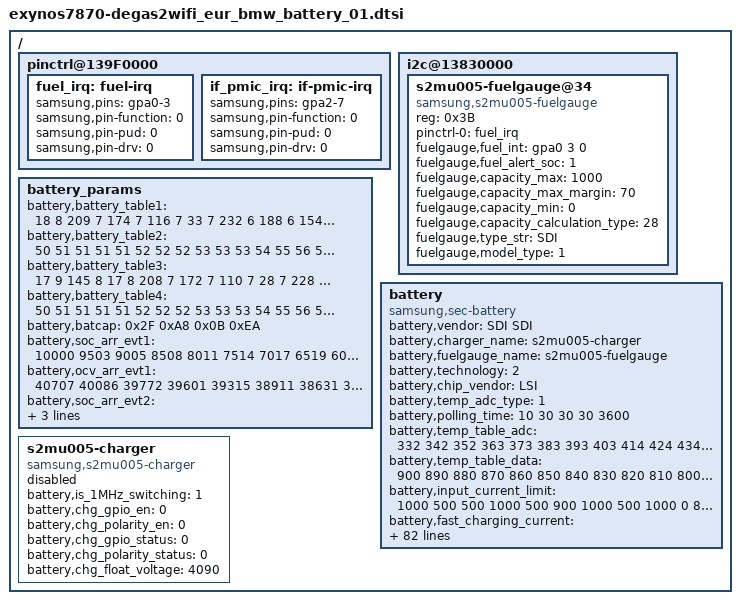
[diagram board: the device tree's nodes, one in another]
/*
 * SAMSUNG UNIVERSAL5433 board device tree source
 *
 * Copyright (c) 2015 Samsung Electronics Co., Ltd.
 *		http://www.samsung.com
 *
 * This program is free software; you can redistribute it and/or modify
 * it under the terms of the GNU General Public License version 2 as
 * published by the Free Software Foundation.
*/

/ {
	pinctrl@139F0000 {
		fuel_irq: fuel-irq {
			samsung,pins = "gpa0-3";
			samsung,pin-function = <0>;
			samsung,pin-pud = <0>;
			samsung,pin-drv = <0>;
		};
	};

	pinctrl@139F0000 {
		if_pmic_irq: if-pmic-irq {
			samsung,pins = "gpa2-7";
			samsung,pin-function = <0>;
			samsung,pin-pud = <0>;
			samsung,pin-drv = <0>;
		};
	};

	i2c@13830000 {
		status = "okay";
		s2mu005-fuelgauge@34 {
			compatible = "samsung,s2mu005-fuelgauge";
			reg = <0x3B>;
			pinctrl-names = "default";
			pinctrl-0 = <&fuel_irq>;
			fuelgauge,fuel_int = <&gpa0 3 0>;
			fuelgauge,fuel_alert_soc = <1>;
			fuelgauge,capacity_max = <1000>;
			fuelgauge,capacity_max_margin = <70>;
			fuelgauge,capacity_min = <0>;
			fuelgauge,capacity_calculation_type = <28>;
			fuelgauge,type_str = "SDI";
			fuelgauge,model_type = <1>;
		};
	};

	battery_params {
			battery,battery_table1 = <18 8 209 7 174 7 116 7 33 7 232 6 188 6 154 6 125 6 100 6 78 6 59 6 38 6 19 6 250 5 208 5 156 5 138 5 93 5 109 3 108
			                                      3 109 1 0 8 154 7 52 7 206 6 105 6 3 6 157 5 55 5 209 4 107 4 6 4 160 3 58 3 212 2 111 2 9 2 163 1 61 1 215 0 113 0 12 0 235 15>;

			battery,battery_table2 = <50 51 51 51 51 52 52 52 53 53 53 54 55 56 56 57 57 58 58 59 61 154>;
			
			battery,battery_table3 = <17 9 145 8 17 8 208 7 172 7 110 7 28 7 228 6 185 6 150 6 121 6 97 6 75 6 55 6 34 6 13 6 240 5 195 5 151 5 125 5 198 
			                                     4 109 1 103 8 0 8 153 7 49 7 202 6 98 6 251 5 147 5 44 5 196 4 93 4 246 3 142 3 39 3 191 2 88 2 240 1 137 1 33 1 186 0 83 0 235 15>;
			battery,battery_table4 = <50 51 51 51 51 52 52 52 53 53 53 54 55 56 56 57 57 58 58 59 61 154>;

			battery,batcap = <0x2F 0xA8 0x0B 0xEA>; /* [0x0F] [0x0E] [0x11] [0x10] */
			
			battery,soc_arr_evt1 = <10000 9503 9005 8508 8011 7514 7017 6519 6022 5525 5028 4531 4034 3537 3040 2542 2046 1549 1052 554 57 (-100)>;
			battery,ocv_arr_evt1 = <40707 40086 39772 39601 39315 38911 38631 38420 38252 38110 37989 37882 37788 37688 37593 37473 37265 37010 36923 36705 34276 31700>;
			
			battery,soc_arr_evt2 = <10000 9503 9005 8508 8011 7514 7017 6519 6022 5525 5028 4531 4034 3537 3040 2542 2046 1549 1052 554 57 (-100)>;
			battery,ocv_arr_evt2 = <40707 40086 39772 39601 39315 38911 38631 38420 38252 38110 37989 37882 37788 37688 37593 37473 37265 37010 36923 36705 34276 31700>;
	};

	battery {
		status = "okay";

		pinctrl-names = "default";

		compatible = "samsung,sec-battery";
		battery,vendor = "SDI SDI";
		battery,charger_name = "s2mu005-charger";
		battery,fuelgauge_name = "s2mu005-fuelgauge";
		battery,technology = <2>; /* POWER_SUPPLY_TECHNOLOGY_LION */

		battery,chip_vendor = "LSI";
		battery,temp_adc_type = <1>; /* SEC_BATTERY_ADC_TYPE_AP */

		battery,polling_time = <10 30 30 30 3600>;

		battery,temp_table_adc = <332 342 352 363 373 383 393 403 414 424 434 450 466 482 498 515 530
					546 561 577 593 610 627 644 661 681 701 722 744 769 794 817 841 856 872
					924 966 1007 1022 1038 1068 1099 1136 1170 1205 1242 1288 1324 1360 1409 1459
					1495 1532 1568 1605 1642 1692 1743 1793 1844 1895 1933 1972 2010 2049 2088 2126
					2165 2203 2242 2281 2317 2353 2389 2425 2461 2509 2557 2605 2653 2702 2734 2767
					2800 2832 2865 2898 2931 2965 2998 3030 3060 3090 3118 3147 3177 3214 3239 3263
					3288 3313 3331 3349 3367 3386 3404 3409 3418 3426 3434 3442>;

		battery,temp_table_data = <900 890 880 870 860 850 840 830 820 810 800 790 780 770 760 750 740 730 720 710 700 690
					   680 670 660 650 640 630 620 610 600 590 580 570 560 550 540 530 520 510 500 490 480 470
					   460 450 440 430 420 410 400 390 380 370 360 350 340 330 320 310 300 290 280 270 260 250
					   240 230 220 210 200 190 180 170 160 150 140 130 120 110 100 90 80 70 60 50 40 30 20 10
					   0 (-10) (-20) (-30) (-40) (-50) (-60) (-70) (-80) (-90) (-100) (-110) (-120) (-130) (-140)
					   (-150) (-160) (-170) (-180) (-190) (-200)>;

		battery,input_current_limit = <1000 500 500 1000 500 900 1000 500 1000 0 820 820 820 1000 1000 0 0 400 700 1000 300 1000 1000 0 1000 1000 1000 1000 80 1000 1000 1000 1000 1000 820 820>;
		battery,fast_charging_current = <1000 0 0 1000 500 1000 1000 500 1000 0 1000 1000 1000 1000 1000 0 0 400 700 1000 300 1000 1000 0 1000 1000 1000 1000 80 1000 1000 1000 0 1000 1000 1000>;
		battery,full_check_current_1st = <200 0 0 200 200 200 200 200 200 0 200 200 200 200 200 0 0 200 200 200 200 200 200 0 200 200 200 200 0 200 200 200 0 200 200 200>;
		battery,full_check_current_2nd = <150 0 0 150 150 150 150 150 150 0 150 150 150 150 150 0 0 150 150 150 150 150 150 0 150 150 150 150 0 150 150 150 0 150 150 150>;

		battery,wireless_cc_cv = <86>;
		battery,inbat_voltage = <0>;
		battery,inbat_voltage_table_adc = <3120 3101 3061 3038 3001 2956 2920 2887 2856 2814
						2793 2754 2720 2677 2641 2613 2572 2531 2502 2467 2436>;
		battery,inbat_voltage_table_data = <438 435 430 425 420 415 410 405 400 395
						390 385 380 375 370 365 360 355 350 345 340>;

		battery,adc_check_count = <5>;

		battery,cable_check_type = <4>; /* SEC_BATTERY_CABLE_CHECK_PSY */
		battery,cable_source_type = <1>; /* SEC_BATTERY_CABLE_SOURCE_EXTERNAL */
		battery,polling_type = <1>; /* SEC_BATTERY_MONITOR_ALARM */
		battery,monitor_initial_count = <0>;

		battery,battery_check_type = <0>; /* SEC_BATTERY_CHECK_NONE */
		battery,check_count = <0>;

		battery,check_adc_max = <1440>;
		battery,check_adc_min = <0>;

		battery,ovp_uvlo_check_type = <3>; /* SEC_BATTERY_OVP_UVLO_CHGPOLLING */

		battery,thermal_source = <2>; /* SEC_BATTERY_THERMAL_SOURCE_ADC */

		battery,temp_check_type = <2>; /* SEC_BATTERY_TEMP_CHECK_TEMP */
		battery,temp_check_count = <1>;
		battery,temp_highlimit_threshold_normal = <800>;
		battery,temp_highlimit_recovery_normal = <750>;
		battery,temp_high_threshold_normal = <500>;
		battery,temp_high_recovery_normal = <450>;
		battery,temp_low_threshold_normal = <0>;
		battery,temp_low_recovery_normal = <5>;
		battery,temp_highlimit_threshold_lpm = <800>;
		battery,temp_highlimit_recovery_lpm = <750>;
		battery,temp_high_threshold_lpm = <500>;
		battery,temp_high_recovery_lpm = <450>;
		battery,temp_low_threshold_lpm = <0>;
		battery,temp_low_recovery_lpm = <5>;
		battery,full_check_type = <2>; /* SEC_BATTERY_FULLCHARGED_FG_CURRENT */
		battery,full_check_type_2nd = <0>; /* NONE */
		battery,full_check_count = <1>;
		battery,chg_gpio_full_check = <0>;
		battery,chg_polarity_full_check = <1>;

		battery,chg_high_temp_1st = <530>;
		battery,chg_high_temp_2nd = <530>;
		battery,chg_high_temp_recovery = <525>;
		battery,chg_charging_limit_current = <1300>;
		battery,chg_charging_limit_current_2nd = <1300>;
		battery,chg_skip_check_capacity = <10>;
		battery,chg_skip_check_time = <600>;

		battery,wpc_high_temp = <420>;
		battery,wpc_high_temp_recovery = <410>;
		battery,wpc_charging_limit_current = <450>;

		/* SEC_BATTERY_FULL_CONDITION_SOC |
		   SEC_BATTERY_FULL_CONDITION_NOTIMEFULL |
		   SEC_BATTERY_FULL_CONDITION_VCELL */
		battery,full_condition_type = <15>;
		battery,full_condition_soc = <93>;
		battery,full_condition_vcell = <4000>;

		battery,recharge_check_count = <2>;
		battery,recharge_condition_type = <4>; /* SEC_BATTERY_RECHARGE_CONDITION_VCELL */
		battery,recharge_condition_soc = <98>;
		battery,recharge_condition_vcell = <4040>;

		battery,charging_total_time = <21600>;
		battery,recharging_total_time = <5400>;
		battery,charging_reset_time = <0>;


		io-channels = <&exynos_adc 1>;
		io-channel-names = "adc-temp";
		#io-channel-cells = <1>;
		io-channel-ranges;

		battery,chg_float_voltage = <4090>;

		battery,self_discharging_en;
		battery,force_discharging_limit = <650>;
		battery,force_discharging_recov = <550>;
		battery,self_discharging_voltage_limit = <4250>;
		battery,discharging_adc_max = <2600>;
		battery,discharging_adc_min = <1700>;
		battery,discharging_ntc_limit = <2750>;

		battery,swelling_high_temp_block = <450>;
		battery,swelling_high_temp_recov = <400>;
		battery,swelling_low_temp_block = <100>;
		battery,swelling_low_temp_recov = <150>;
		battery,swelling_low_temp_current = <1400>;	/* 0.5C */
		battery,swelling_low_temp_topoff = <140>;	/* 0.05C */
		battery,swelling_high_temp_current = <1500>;	/* 0.7C */
		battery,swelling_high_temp_topoff = <140>;	/* 0.05C */
		battery,swelling_drop_float_voltage = <4200>;
		battery,swelling_high_rechg_voltage = <4150>;
		battery,swelling_low_rechg_voltage = <4050>;
	};

	s2mu005-charger {
		status = "disable";
		compatible = "samsung,s2mu005-charger";
		battery,is_1MHz_switching = <1>;
		battery,chg_gpio_en = <0>;
		battery,chg_polarity_en = <0>;
		battery,chg_gpio_status = <0>;
		battery,chg_polarity_status = <0>;
		battery,chg_float_voltage = <4090>;
	};
};
